AUTOSAR XML (schema 4-2-1)
package /RootP_IntDcm
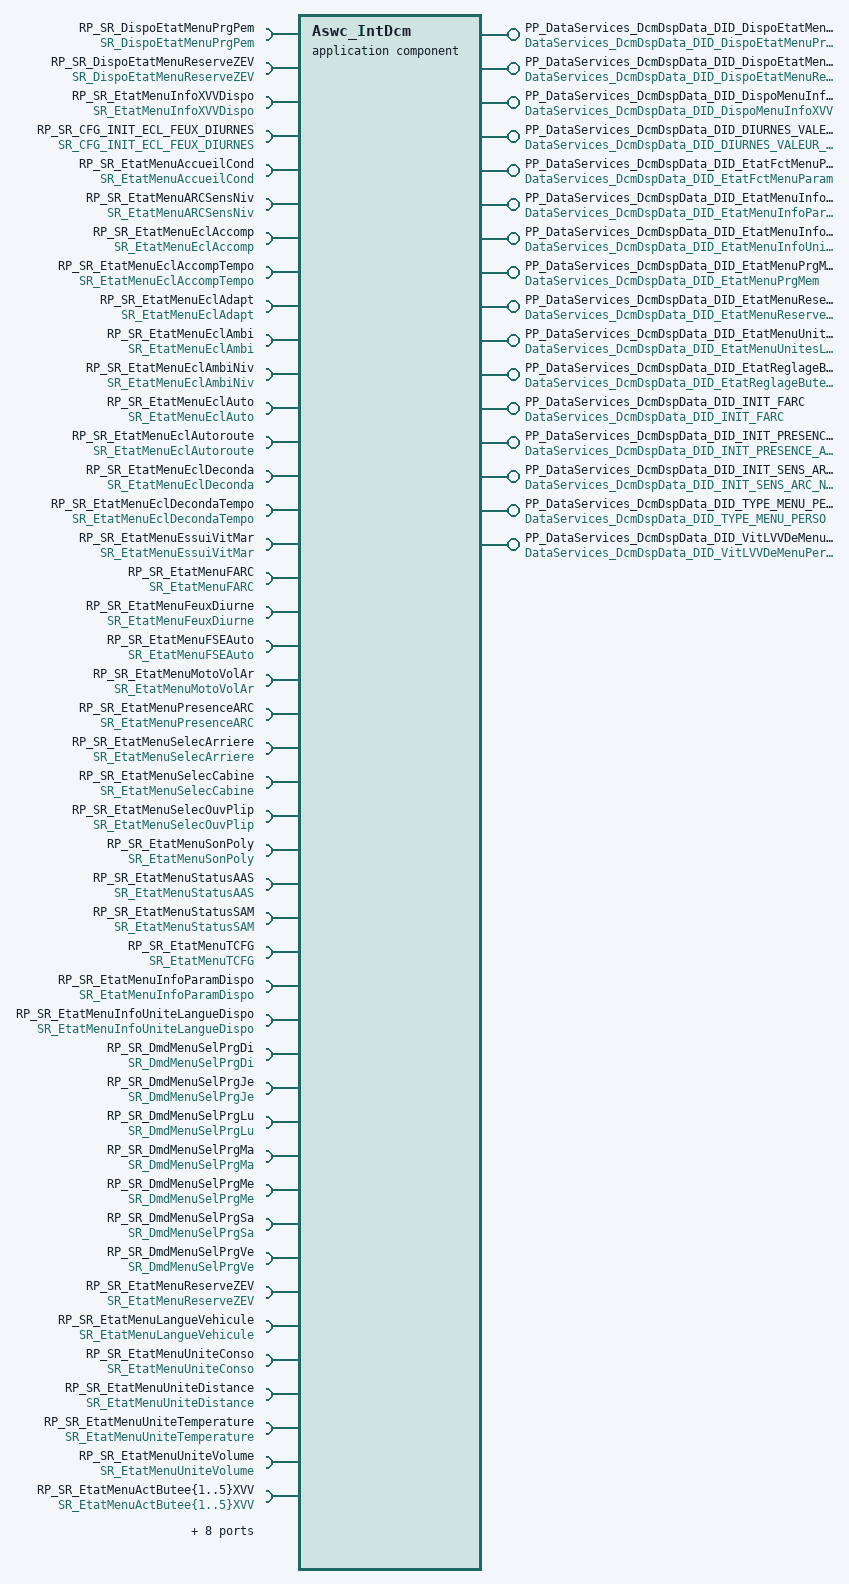
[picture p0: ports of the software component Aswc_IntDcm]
  application sw component type Aswc_IntDcm
    16 x provide port:
      PP_DataServices_DcmDspData_DID_DispoEtatMenuPrgPem: server-com-spec{operation=DataServices_DcmDspData_DID_DispoEtatMenuPrgPem/ReadData, queue-length=1}, provided-interface=DataServices_DcmDspData_DID_DispoEtatMenuPrgPem
      PP_DataServices_DcmDspData_DID_DispoEtatMenuReserveZEV: server-com-spec{operation=DataServices_DcmDspData_DID_DispoEtatMenuReserveZEV/ReadData, queue-length=1}, provided-interface=DataServices_DcmDspData_DID_DispoEtatMenuReserveZEV
      PP_DataServices_DcmDspData_DID_DispoMenuInfoXVV: server-com-spec{operation=DataServices_DcmDspData_DID_DispoMenuInfoXVV/ReadData, queue-length=1}, provided-interface=DataServices_DcmDspData_DID_DispoMenuInfoXVV
      PP_DataServices_DcmDspData_DID_DIURNES_VALEUR_DEFAUT: provided-interface=DataServices_DcmDspData_DID_DIURNES_VALEUR_DEFAUT
        provided-com-specs:
          operation=DataServices_DcmDspData_DID_DIURNES_VALEUR_DEFAUT/ReadData, queue-length=1
          operation=DataServices_DcmDspData_DID_DIURNES_VALEUR_DEFAUT/WriteData, queue-length=1
      PP_DataServices_DcmDspData_DID_EtatFctMenuParam: server-com-spec{operation=DataServices_DcmDspData_DID_EtatFctMenuParam/ReadData, queue-length=1}, provided-interface=DataServices_DcmDspData_DID_EtatFctMenuParam
      PP_DataServices_DcmDspData_DID_EtatMenuInfoParamDispo: server-com-spec{operation=DataServices_DcmDspData_DID_EtatMenuInfoParamDispo/ReadData, queue-length=1}, provided-interface=DataServices_DcmDspData_DID_EtatMenuInfoParamDispo
      PP_DataServices_DcmDspData_DID_EtatMenuInfoUniteLangueDispo: server-com-spec{operation=DataServices_DcmDspData_DID_EtatMenuInfoUniteLangueDispo/ReadData, queue-length=1}, provided-interface=DataServices_DcmDspData_DID_EtatMenuInfoUniteLangueDispo
      PP_DataServices_DcmDspData_DID_EtatMenuPrgMem: provided-interface=DataServices_DcmDspData_DID_EtatMenuPrgMem
        provided-com-specs:
          operation=DataServices_DcmDspData_DID_EtatMenuPrgMem/ReadData, queue-length=1
          operation=DataServices_DcmDspData_DID_EtatMenuPrgMem/WriteData, queue-length=1
      PP_DataServices_DcmDspData_DID_EtatMenuReserveZEV: server-com-spec{operation=DataServices_DcmDspData_DID_EtatMenuReserveZEV/ReadData, queue-length=1}, provided-interface=DataServices_DcmDspData_DID_EtatMenuReserveZEV
      PP_DataServices_DcmDspData_DID_EtatMenuUnitesLangue: server-com-spec{operation=DataServices_DcmDspData_DID_EtatMenuUnitesLangue/ReadData, queue-length=1}, provided-interface=DataServices_DcmDspData_DID_EtatMenuUnitesLangue
      PP_DataServices_DcmDspData_DID_EtatReglageButeesXVV: server-com-spec{operation=DataServices_DcmDspData_DID_EtatReglageButeesXVV/ReadData, queue-length=1}, provided-interface=DataServices_DcmDspData_DID_EtatReglageButeesXVV
      PP_DataServices_DcmDspData_DID_INIT_FARC: provided-interface=DataServices_DcmDspData_DID_INIT_FARC
        provided-com-specs:
          operation=DataServices_DcmDspData_DID_INIT_FARC/ReadData, queue-length=1
          operation=DataServices_DcmDspData_DID_INIT_FARC/WriteData, queue-length=1
      PP_DataServices_DcmDspData_DID_INIT_PRESENCE_ARC: provided-interface=DataServices_DcmDspData_DID_INIT_PRESENCE_ARC
        provided-com-specs:
          operation=DataServices_DcmDspData_DID_INIT_PRESENCE_ARC/ReadData, queue-length=1
          operation=DataServices_DcmDspData_DID_INIT_PRESENCE_ARC/WriteData, queue-length=1
      PP_DataServices_DcmDspData_DID_INIT_SENS_ARC_NIV: provided-interface=DataServices_DcmDspData_DID_INIT_SENS_ARC_NIV
        provided-com-specs:
          operation=DataServices_DcmDspData_DID_INIT_SENS_ARC_NIV/ReadData, queue-length=1
          operation=DataServices_DcmDspData_DID_INIT_SENS_ARC_NIV/WriteData, queue-length=1
      PP_DataServices_DcmDspData_DID_TYPE_MENU_PERSO: provided-interface=DataServices_DcmDspData_DID_TYPE_MENU_PERSO
        provided-com-specs:
          operation=DataServices_DcmDspData_DID_TYPE_MENU_PERSO/ReadData, queue-length=1
          operation=DataServices_DcmDspData_DID_TYPE_MENU_PERSO/WriteData, queue-length=1
      PP_DataServices_DcmDspData_DID_VitLVVDeMenuPerso: server-com-spec{operation=DataServices_DcmDspData_DID_VitLVVDeMenuPerso/ReadData, queue-length=1}, provided-interface=DataServices_DcmDspData_DID_VitLVVDeMenuPerso
    12 x provide/require port:
      PP_SR_CFG_INIT_ECL_FEUX_DIURNES: provided-required-interface=SR_CFG_INIT_ECL_FEUX_DIURNES
      PP_SR_DmdMenuSelPrgDi: provided-required-interface=SR_DmdMenuSelPrgDi
      PP_SR_DmdMenuSelPrgJe: provided-required-interface=SR_DmdMenuSelPrgJe
      PP_SR_DmdMenuSelPrgLu: provided-required-interface=SR_DmdMenuSelPrgLu
      PP_SR_DmdMenuSelPrgMa: provided-required-interface=SR_DmdMenuSelPrgMa
      PP_SR_DmdMenuSelPrgMe: provided-required-interface=SR_DmdMenuSelPrgMe
      PP_SR_DmdMenuSelPrgSa: provided-required-interface=SR_DmdMenuSelPrgSa
      PP_SR_DmdMenuSelPrgVe: provided-required-interface=SR_DmdMenuSelPrgVe
      PP_SR_CFG_INIT_FARC: provided-required-interface=SR_CFG_INIT_FARC
      PP_SR_CFG_INIT_PRESENCE_ARC: provided-required-interface=SR_CFG_INIT_PRESENCE_ARC
      PP_SR_CFG_INIT_SENS_ARC_NIV: provided-required-interface=SR_CFG_INIT_SENS_ARC_NIV
      PP_SR_CFG_PRESENCE_MENU_PERSO: provided-required-interface=SR_CFG_PRESENCE_MENU_PERSO
    65 x require port:
      RP_SR_DispoEtatMenuPrgPem: required-interface=SR_DispoEtatMenuPrgPem
      RP_SR_DispoEtatMenuReserveZEV: required-interface=SR_DispoEtatMenuReserveZEV
      RP_SR_EtatMenuInfoXVVDispo: required-interface=SR_EtatMenuInfoXVVDispo
      RP_SR_CFG_INIT_ECL_FEUX_DIURNES: required-interface=SR_CFG_INIT_ECL_FEUX_DIURNES
      RP_SR_EtatMenuAccueilCond: required-interface=SR_EtatMenuAccueilCond
      RP_SR_EtatMenuARCSensNiv: required-interface=SR_EtatMenuARCSensNiv
      RP_SR_EtatMenuEclAccomp: required-interface=SR_EtatMenuEclAccomp
      RP_SR_EtatMenuEclAccompTempo: required-interface=SR_EtatMenuEclAccompTempo
      RP_SR_EtatMenuEclAdapt: required-interface=SR_EtatMenuEclAdapt
      RP_SR_EtatMenuEclAmbi: required-interface=SR_EtatMenuEclAmbi
      RP_SR_EtatMenuEclAmbiNiv: required-interface=SR_EtatMenuEclAmbiNiv
      RP_SR_EtatMenuEclAuto: required-interface=SR_EtatMenuEclAuto
      RP_SR_EtatMenuEclAutoroute: required-interface=SR_EtatMenuEclAutoroute
      RP_SR_EtatMenuEclDeconda: required-interface=SR_EtatMenuEclDeconda
      RP_SR_EtatMenuEclDecondaTempo: required-interface=SR_EtatMenuEclDecondaTempo
      RP_SR_EtatMenuEssuiVitMar: required-interface=SR_EtatMenuEssuiVitMar
      RP_SR_EtatMenuFARC: required-interface=SR_EtatMenuFARC
      RP_SR_EtatMenuFeuxDiurne: required-interface=SR_EtatMenuFeuxDiurne
      RP_SR_EtatMenuFSEAuto: required-interface=SR_EtatMenuFSEAuto
      RP_SR_EtatMenuMotoVolAr: required-interface=SR_EtatMenuMotoVolAr
      RP_SR_EtatMenuPresenceARC: required-interface=SR_EtatMenuPresenceARC
      RP_SR_EtatMenuSelecArriere: required-interface=SR_EtatMenuSelecArriere
      RP_SR_EtatMenuSelecCabine: required-interface=SR_EtatMenuSelecCabine
      RP_SR_EtatMenuSelecOuvPlip: required-interface=SR_EtatMenuSelecOuvPlip
      RP_SR_EtatMenuSonPoly: required-interface=SR_EtatMenuSonPoly
      RP_SR_EtatMenuStatusAAS: required-interface=SR_EtatMenuStatusAAS
      RP_SR_EtatMenuStatusSAM: required-interface=SR_EtatMenuStatusSAM
      RP_SR_EtatMenuTCFG: required-interface=SR_EtatMenuTCFG
      RP_SR_EtatMenuInfoParamDispo: required-interface=SR_EtatMenuInfoParamDispo
      RP_SR_EtatMenuInfoUniteLangueDispo: required-interface=SR_EtatMenuInfoUniteLangueDispo
      RP_SR_DmdMenuSelPrgDi: required-interface=SR_DmdMenuSelPrgDi
      RP_SR_DmdMenuSelPrgJe: required-interface=SR_DmdMenuSelPrgJe
      RP_SR_DmdMenuSelPrgLu: required-interface=SR_DmdMenuSelPrgLu
      RP_SR_DmdMenuSelPrgMa: required-interface=SR_DmdMenuSelPrgMa
      RP_SR_DmdMenuSelPrgMe: required-interface=SR_DmdMenuSelPrgMe
      RP_SR_DmdMenuSelPrgSa: required-interface=SR_DmdMenuSelPrgSa
      RP_SR_DmdMenuSelPrgVe: required-interface=SR_DmdMenuSelPrgVe
      RP_SR_EtatMenuReserveZEV: required-interface=SR_EtatMenuReserveZEV
      RP_SR_EtatMenuLangueVehicule: required-interface=SR_EtatMenuLangueVehicule
      RP_SR_EtatMenuUniteConso: required-interface=SR_EtatMenuUniteConso
      RP_SR_EtatMenuUniteDistance: required-interface=SR_EtatMenuUniteDistance
      RP_SR_EtatMenuUniteTemperature: required-interface=SR_EtatMenuUniteTemperature
      RP_SR_EtatMenuUniteVolume: required-interface=SR_EtatMenuUniteVolume
      RP_SR_EtatMenuActButee{1..5}XVV: required-interface=SR_EtatMenuActButee{1..5}XVV
      RP_SR_EtatMenuActButeeGenXVV: required-interface=SR_EtatMenuActButeeGenXVV
      RP_SR_EtatMenuVitesse{1..5}XVV: required-interface=SR_EtatMenuVitesse{1..5}XVV
      RP_SR_CFG_INIT_FARC: required-interface=SR_CFG_INIT_FARC
      RP_SR_CFG_INIT_PRESENCE_ARC: required-interface=SR_CFG_INIT_PRESENCE_ARC
      RP_SR_CFG_INIT_SENS_ARC_NIV: required-interface=SR_CFG_INIT_SENS_ARC_NIV
      RP_SR_CFG_PRESENCE_MENU_PERSO: required-interface=SR_CFG_PRESENCE_MENU_PERSO
      RP_SR_EtatMenuVitLvv{1..6}: required-interface=SR_EtatMenuVitLvv{1..6}
      Aswc_IntDcm_MSI: required-interface=RootP_RteMode
    behavior IB_Aswc_IntDcm: data-type-mapping=ApplicationModeMapping, handle-termination-and-restart=NO-SUPPORT
      22 x operation invoked event:
        DataServices_DcmDspData_DID_DispoEtatMenuPrgPem_ReadData_OIE: start-on-event=RUNS_DID_DispoEtatMenuPrgPem_Get, operation=PP_DataServices_DcmDspData_DID_DispoEtatMenuPrgPem.ReadData
        DataServices_DcmDspData_DID_DispoEtatMenuReserveZEV_ReadData_OIE: start-on-event=RUNS_DID_DispoEtatMenuReserveZEV_Get, operation=PP_DataServices_DcmDspData_DID_DispoEtatMenuReserveZEV.ReadData
        DataServices_DcmDspData_DID_DispoMenuInfoXVV_ReadData_OIE: start-on-event=RUNS_DID_DispoMenuInfoXVV_Get, operation=PP_DataServices_DcmDspData_DID_DispoMenuInfoXVV.ReadData
        DataServices_DcmDspData_DID_DIURNES_VALEUR_DEFAUT_ReadData_OIE: start-on-event=RUNS_DID_DIURNES_VALEUR_DEFAUT_Get, operation=PP_DataServices_DcmDspData_DID_DIURNES_VALEUR_DEFAUT.ReadData
        DataServices_DcmDspData_DID_DIURNES_VALEUR_DEFAUT_WriteData_OIE: start-on-event=RUNS_DID_DIURNES_VALEUR_DEFAUT_Set, operation=PP_DataServices_DcmDspData_DID_DIURNES_VALEUR_DEFAUT.WriteData
        DataServices_DcmDspData_DID_EtatFctMenuParam_ReadData_OIE: start-on-event=RUNS_DID_EtatFctMenuParam_Get, operation=PP_DataServices_DcmDspData_DID_EtatFctMenuParam.ReadData
        DataServices_DcmDspData_DID_EtatMenuInfoParamDispo_ReadData_OIE: start-on-event=RUNS_DID_EtatMenuInfoParamDispo_Get, operation=PP_DataServices_DcmDspData_DID_EtatMenuInfoParamDispo.ReadData
        DataServices_DcmDspData_DID_EtatMenuInfoUniteLangueDispo_ReadData_OIE: start-on-event=RUNS_DID_EtatMenuInfoUniteLangueDispo_Get, operation=PP_DataServices_DcmDspData_DID_EtatMenuInfoUniteLangueDispo.ReadData
        DataServices_DcmDspData_DID_EtatMenuPrgMem_ReadData_OIE: start-on-event=RUNS_DID_EtatMenuPrgMem_Get, operation=PP_DataServices_DcmDspData_DID_EtatMenuPrgMem.ReadData
        DataServices_DcmDspData_DID_EtatMenuPrgMem_WriteData_OIE: start-on-event=RUNS_DID_EtatMenuPrgMem_Set, operation=PP_DataServices_DcmDspData_DID_EtatMenuPrgMem.WriteData
        DataServices_DcmDspData_DID_EtatMenuReserveZEV_ReadData_OIE: start-on-event=RUNS_DID_EtatMenuReserveZEV_Get, operation=PP_DataServices_DcmDspData_DID_EtatMenuReserveZEV.ReadData
        DataServices_DcmDspData_DID_EtatMenuUnitesLangue_ReadData_OIE: start-on-event=RUNS_DID_EtatMenuUnitesLangue_Get, operation=PP_DataServices_DcmDspData_DID_EtatMenuUnitesLangue.ReadData
        DataServices_DcmDspData_DID_EtatReglageButeesXVV_ReadData_OIE: start-on-event=RUNS_DID_EtatReglageButeesXVV_Get, operation=PP_DataServices_DcmDspData_DID_EtatReglageButeesXVV.ReadData
        DataServices_DcmDspData_DID_INIT_FARC_ReadData_OIE: start-on-event=RUNS_DID_INIT_FARC_Get, operation=PP_DataServices_DcmDspData_DID_INIT_FARC.ReadData
        DataServices_DcmDspData_DID_INIT_FARC_WriteData_OIE: start-on-event=RUNS_DID_INIT_FARC_Set, operation=PP_DataServices_DcmDspData_DID_INIT_FARC.WriteData
        DataServices_DcmDspData_DID_INIT_PRESENCE_ARC_ReadData_OIE: start-on-event=RUNS_DID_INIT_PRESENCE_ARC_Get, operation=PP_DataServices_DcmDspData_DID_INIT_PRESENCE_ARC.ReadData
        DataServices_DcmDspData_DID_INIT_PRESENCE_ARC_WriteData_OIE: start-on-event=RUNS_DID_INIT_PRESENCE_ARC_Set, operation=PP_DataServices_DcmDspData_DID_INIT_PRESENCE_ARC.WriteData
        DataServices_DcmDspData_DID_INIT_SENS_ARC_NIV_ReadData_OIE: start-on-event=RUNS_DID_INIT_SENS_ARC_NIV_Get, operation=PP_DataServices_DcmDspData_DID_INIT_SENS_ARC_NIV.ReadData
        DataServices_DcmDspData_DID_INIT_SENS_ARC_NIV_WriteData_OIE: start-on-event=RUNS_DID_INIT_SENS_ARC_NIV_Set, operation=PP_DataServices_DcmDspData_DID_INIT_SENS_ARC_NIV.WriteData
        DataServices_DcmDspData_DID_TYPE_MENU_PERSO_ReadData_OIE: start-on-event=RUNS_DID_TYPE_MENU_PERSO_Get, operation=PP_DataServices_DcmDspData_DID_TYPE_MENU_PERSO.ReadData
        DataServices_DcmDspData_DID_TYPE_MENU_PERSO_WriteData_OIE: start-on-event=RUNS_DID_TYPE_MENU_PERSO_Set, operation=PP_DataServices_DcmDspData_DID_TYPE_MENU_PERSO.WriteData
        DataServices_DcmDspData_DID_VitLVVDeMenuPerso_ReadData_OIE: start-on-event=RUNS_DID_VitLVVDeMenuPerso_Get, operation=PP_DataServices_DcmDspData_DID_VitLVVDeMenuPerso.ReadData
      swc mode switch event RUNPI_Aswc_IntDcm_ENTRY: start-on-event=RUNPI_Aswc_IntDcm, activation=ON-ENTRY, mode=Aswc_IntDcm_MSI.RteMode.APP_WAKEUP
      23 x runnable:
        RUNS_DID_DispoEtatMenuPrgPem_Get
        RUNS_DID_DispoEtatMenuReserveZEV_Get
        RUNS_DID_DispoMenuInfoXVV_Get
        RUNS_DID_DIURNES_VALEUR_DEFAUT_Get
        RUNS_DID_DIURNES_VALEUR_DEFAUT_Set
        RUNS_DID_EtatFctMenuParam_Get
        RUNS_DID_EtatMenuInfoParamDispo_Get
        RUNS_DID_EtatMenuInfoUniteLangueDispo_Get
        RUNS_DID_EtatMenuPrgMem_Get
        RUNS_DID_EtatMenuPrgMem_Set
        RUNS_DID_EtatMenuReserveZEV_Get
        RUNS_DID_EtatMenuUnitesLangue_Get
        RUNS_DID_EtatReglageButeesXVV_Get
        RUNS_DID_INIT_FARC_Get
        RUNS_DID_INIT_FARC_Set
        RUNS_DID_INIT_PRESENCE_ARC_Get
        RUNS_DID_INIT_PRESENCE_ARC_Set
        RUNS_DID_INIT_SENS_ARC_NIV_Get
        RUNS_DID_INIT_SENS_ARC_NIV_Set
        RUNS_DID_TYPE_MENU_PERSO_Get
        RUNS_DID_TYPE_MENU_PERSO_Set
        RUNS_DID_VitLVVDeMenuPerso_Get
        RUNPI_Aswc_IntDcm
package /AUTOSAR_Dcm/PortInterfaces
  16 x client server interface, all with is-service=true:
    DataServices_DcmDspData_DID_DispoEtatMenuPrgPem
      operation ReadData
        arg Data: type=tBYTE, direction=OUT
    DataServices_DcmDspData_DID_DispoEtatMenuReserveZEV
      operation ReadData
        arg Data: type=tBYTE, direction=OUT
    DataServices_DcmDspData_DID_DispoMenuInfoXVV
      operation ReadData
        arg Data: type=tBYTE, direction=OUT
    DataServices_DcmDspData_DID_DIURNES_VALEUR_DEFAUT
      operation ReadData
        arg Data: type=tBYTE, direction=OUT
      operation WriteData
        arg Data: type=tBYTE, direction=IN
        arg ErrorCode: type=tBYTE, direction=OUT
    DataServices_DcmDspData_DID_EtatFctMenuParam
      operation ReadData
        arg Data: type=tBYTE, direction=OUT
    DataServices_DcmDspData_DID_EtatMenuInfoParamDispo
      operation ReadData
        arg Data: type=tBYTE, direction=OUT
    DataServices_DcmDspData_DID_EtatMenuInfoUniteLangueDispo
      operation ReadData
        arg Data: type=tBYTE, direction=OUT
    DataServices_DcmDspData_DID_EtatMenuPrgMem
      operation ReadData
        arg Data: type=tBYTE, direction=OUT
      operation WriteData
        arg Data: type=tBYTE, direction=IN
        arg ErrorCode: type=tBYTE, direction=OUT
    DataServices_DcmDspData_DID_EtatMenuReserveZEV
      operation ReadData
        arg Data: type=tBYTE, direction=OUT
    DataServices_DcmDspData_DID_EtatMenuUnitesLangue
      operation ReadData
        arg Data: type=tBYTE, direction=OUT
    DataServices_DcmDspData_DID_EtatReglageButeesXVV
      operation ReadData
        arg Data: type=tBYTE, direction=OUT
    DataServices_DcmDspData_DID_INIT_FARC
      operation ReadData
        arg Data: type=tBYTE, direction=OUT
      operation WriteData
        arg Data: type=tBYTE, direction=IN
        arg ErrorCode: type=tBYTE, direction=OUT
    DataServices_DcmDspData_DID_INIT_PRESENCE_ARC
      operation ReadData
        arg Data: type=tBYTE, direction=OUT
      operation WriteData
        arg Data: type=tBYTE, direction=IN
        arg ErrorCode: type=tBYTE, direction=OUT
    DataServices_DcmDspData_DID_INIT_SENS_ARC_NIV
      operation ReadData
        arg Data: type=tBYTE, direction=OUT
      operation WriteData
        arg Data: type=tBYTE, direction=IN
        arg ErrorCode: type=tBYTE, direction=OUT
    DataServices_DcmDspData_DID_TYPE_MENU_PERSO
      operation ReadData
        arg Data: type=tBYTE, direction=OUT
      operation WriteData
        arg Data: type=tBYTE, direction=IN
        arg ErrorCode: type=tBYTE, direction=OUT
    DataServices_DcmDspData_DID_VitLVVDeMenuPerso
      operation ReadData
        arg Data: type=tBYTE, direction=OUT
